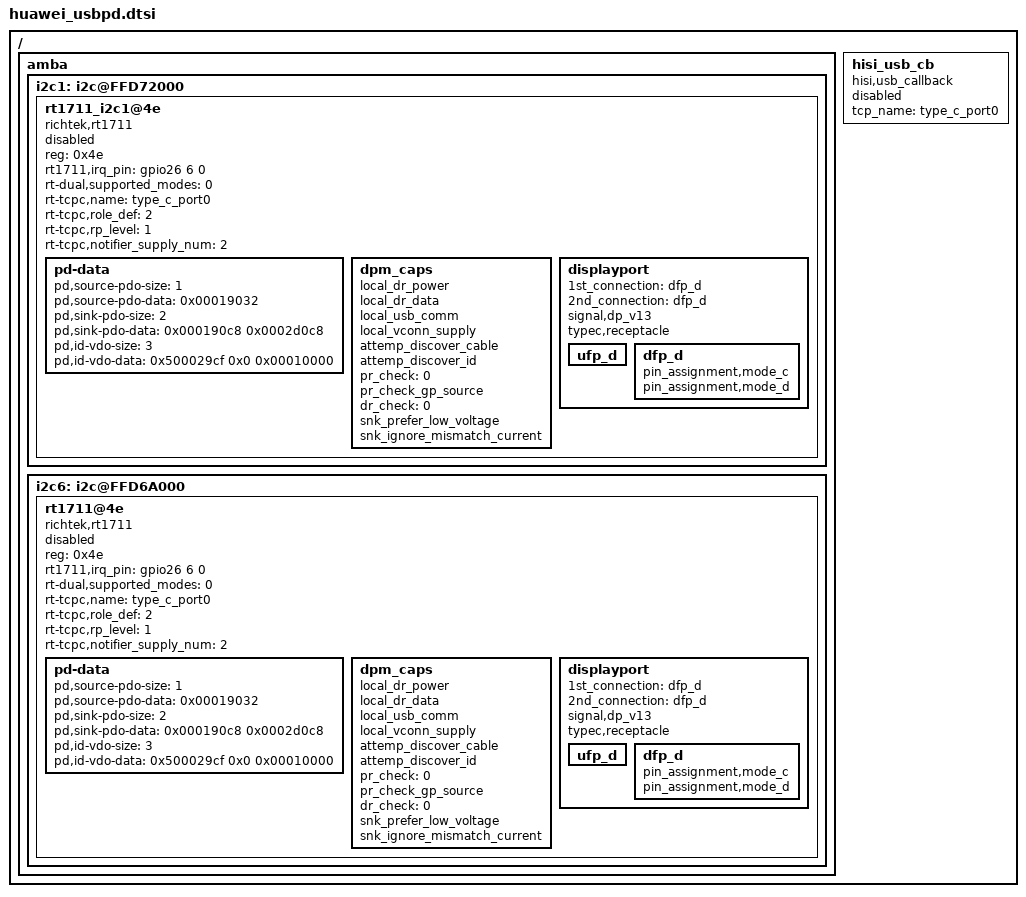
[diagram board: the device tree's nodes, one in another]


/{
	amba{
		i2c1: i2c@FFD72000 {
			rt1711_i2c1@4e {
				compatible = "richtek,rt1711";
				reg = <0x4e>;
				status = "disabled";
				rt1711,irq_pin = <&gpio26 6 0>;
				rt-dual,supported_modes = <0>; /* 0: dfp/ufp, 1: dfp, 2: ufp */
				rt-tcpc,name = "type_c_port0"; /* tcpc_device's name */
				rt-tcpc,role_def = <2>; /* 0: SNK Only, 1: SRC Only, 2: DRP, 3: Try.SRC, 4: Try.SNK */
				rt-tcpc,rp_level = <1>; /* 0: Default, 1: 1.5, 2: 3.0 */
				rt-tcpc,notifier_supply_num = <2>; /* the number of notifier supply */
				pd-data {
					pd,source-pdo-size = <1>;
					pd,source-pdo-data = <0x00019032>; /*<0x019014>;*/

					pd,sink-pdo-size = <2>;
					pd,sink-pdo-data = <0x000190c8 0x0002d0c8> ;   /* 0x0002d0c8 : 9V, 2A */

					/*
					No DP
					pd,id-vdo-size = <3>;
					pd,id-vdo-data = <0x500029cf 0x0 0x00010000>;
					With DP
					pd,id-vdo-size = <4>;
					pd,id-vdo-data = <0xec0029cf 0x0 0x00010000 0x11000001>;
					*/

					pd,id-vdo-size = <3>;
					pd,id-vdo-data = <0x500029cf 0x0 0x00010000>;
				};
				dpm_caps {
					local_dr_power;
					local_dr_data;
					// local_ext_power;
					local_usb_comm;
					// local_usb_suspend;
					// local_high_cap;
					// local_give_back;
					// local_no_suspend;
					local_vconn_supply;

					// attemp_enter_dp_mode;
					attemp_discover_cable;
					attemp_discover_id;

					/* 0: disable, 1: prefer_snk, 2: prefer_src */
					pr_check = <0>;
					// pr_reject_as_source;
					// pr_reject_as_sink;
					pr_check_gp_source;
					// pr_check_gp_sink;

					/* 0: disable, 1: prefer_ufp, 2: prefer_dfp */
					dr_check = <0>;
					// dr_reject_as_dfp;
					// dr_reject_as_ufp;

					snk_prefer_low_voltage;
					snk_ignore_mismatch_current;
				};
				displayport {
					/* connection type = "both", "ufp_d", "dfp_d" */
					1st_connection = "dfp_d";
					2nd_connection = "dfp_d";
					signal,dp_v13;
					//signal,dp_gen2;
					//usbr20_not_used;
					typec,receptacle;
					ufp_d {
						//pin_assignment,mode_a;
						//pin_assignment,mode_b;
						//pin_assignment,mode_c;
						//pin_assignment,mode_d;
						//pin_assignment,mode_e;
					};
					dfp_d {
						/* Only support mode C & D */
						//pin_assignment,mode_a;
						//pin_assignment,mode_b;
						pin_assignment,mode_c;
						pin_assignment,mode_d;
						//pin_assignment,mode_e;
						//pin_assignment,mode_f;
					};
				};
			};
		};
		i2c6: i2c@FFD6A000 {
			rt1711@4e {
				compatible = "richtek,rt1711";
				reg = <0x4e>;
				status = "disabled";
				rt1711,irq_pin = <&gpio26 6 0>;
				rt-dual,supported_modes = <0>; /* 0: dfp/ufp, 1: dfp, 2: ufp */
				rt-tcpc,name = "type_c_port0"; /* tcpc_device's name */
				rt-tcpc,role_def = <2>; /* 0: SNK Only, 1: SRC Only, 2: DRP, 3: Try.SRC, 4: Try.SNK */
				rt-tcpc,rp_level = <1>; /* 0: Default, 1: 1.5, 2: 3.0 */
				rt-tcpc,notifier_supply_num = <2>; /* the number of notifier supply */
				pd-data {
					pd,source-pdo-size = <1>;
					pd,source-pdo-data = <0x00019032>; /*<0x019014>;*/

					pd,sink-pdo-size = <2>;
					pd,sink-pdo-data = <0x000190c8 0x0002d0c8> ;   /* 0x0002d0c8 : 9V, 2A */

					/*
					No DP
					pd,id-vdo-size = <3>;
					pd,id-vdo-data = <0x500029cf 0x0 0x00010000>;
					With DP
					pd,id-vdo-size = <4>;
					pd,id-vdo-data = <0xec0029cf 0x0 0x00010000 0x11000001>;
					*/

					pd,id-vdo-size = <3>;
					pd,id-vdo-data = <0x500029cf 0x0 0x00010000>;
				};
				dpm_caps {
					local_dr_power;
					local_dr_data;
					// local_ext_power;
					local_usb_comm;
					// local_usb_suspend;
					// local_high_cap;
					// local_give_back;
					// local_no_suspend;
					local_vconn_supply;

					// attemp_enter_dp_mode;
					attemp_discover_cable;
					attemp_discover_id;

					/* 0: disable, 1: prefer_snk, 2: prefer_src */
					pr_check = <0>;
					// pr_reject_as_source;
					// pr_reject_as_sink;
					pr_check_gp_source;
					// pr_check_gp_sink;

					/* 0: disable, 1: prefer_ufp, 2: prefer_dfp */
					dr_check = <0>;
					// dr_reject_as_dfp;
					// dr_reject_as_ufp;

					snk_prefer_low_voltage;
					snk_ignore_mismatch_current;
				};
				displayport {
					/* connection type = "both", "ufp_d", "dfp_d" */
					1st_connection = "dfp_d";
					2nd_connection = "dfp_d";
					signal,dp_v13;
					//signal,dp_gen2;
					//usbr20_not_used;
					typec,receptacle;
					ufp_d {
						//pin_assignment,mode_a;
						//pin_assignment,mode_b;
						//pin_assignment,mode_c;
						//pin_assignment,mode_d;
						//pin_assignment,mode_e;
					};
					dfp_d {
						/* Only support mode C & D */
						//pin_assignment,mode_a;
						//pin_assignment,mode_b;
						pin_assignment,mode_c;
						pin_assignment,mode_d;
						//pin_assignment,mode_e;
						//pin_assignment,mode_f;
					};
				};
			};
		};
	};

	hisi_usb_cb {
		compatible = "hisi,usb_callback";
		tcp_name = "type_c_port0";
		status = "disabled";
	};

};
